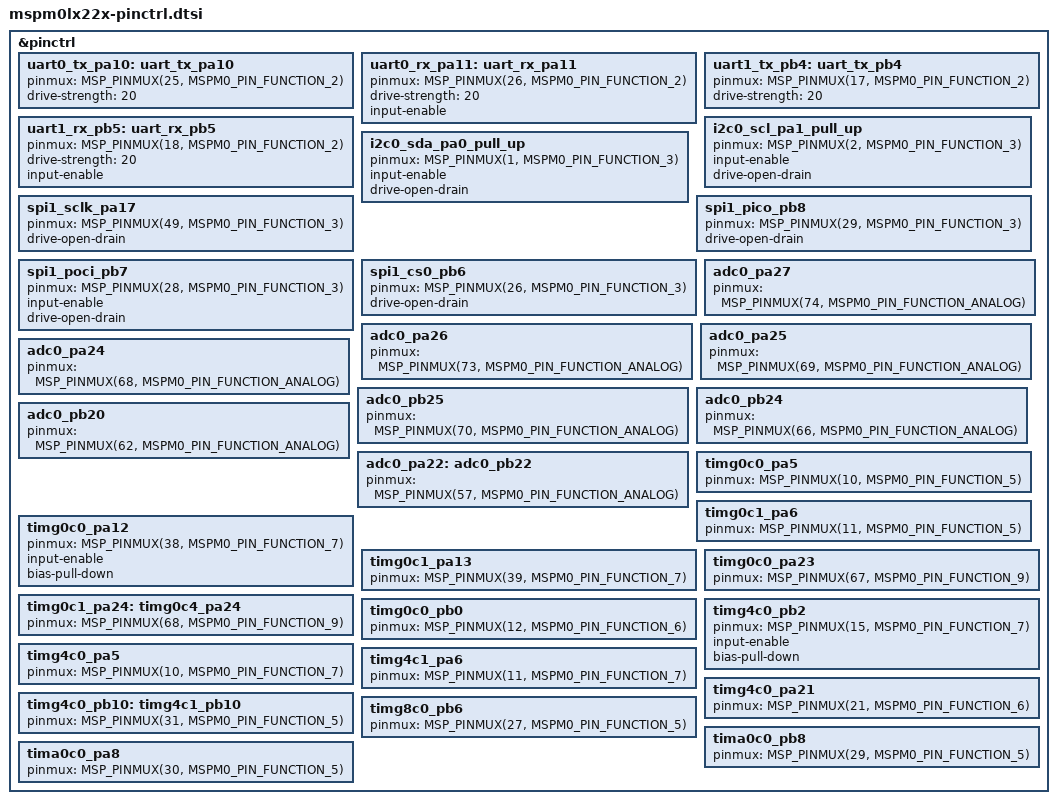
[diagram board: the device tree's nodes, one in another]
#include <dt-bindings/pinctrl/mspm0-pinctrl.h>

&pinctrl {
	/omit-if-no-ref/ uart0_tx_pa10: uart_tx_pa10 {
		pinmux = <MSP_PINMUX(25, MSPM0_PIN_FUNCTION_2)>;
		drive-strength = <20>;
	};

	/omit-if-no-ref/ uart0_rx_pa11: uart_rx_pa11 {
		pinmux = <MSP_PINMUX(26, MSPM0_PIN_FUNCTION_2)>;
		drive-strength = <20>;
		input-enable;
	};

	/omit-if-no-ref/ uart1_tx_pb4: uart_tx_pb4 {
		pinmux = <MSP_PINMUX(17, MSPM0_PIN_FUNCTION_2)>;
		drive-strength = <20>;
	};

	/omit-if-no-ref/ uart1_rx_pb5: uart_rx_pb5 {
		pinmux = <MSP_PINMUX(18, MSPM0_PIN_FUNCTION_2)>;
		drive-strength = <20>;
		input-enable;
	};

	/omit-if-no-ref/ i2c0_scl_pa1_pull_up: i2c0_scl_pa1_pull_up {
		pinmux = <MSP_PINMUX(2, MSPM0_PIN_FUNCTION_3)>;
		input-enable;
		drive-open-drain;
	};

	/omit-if-no-ref/ i2c0_sda_pa0_pull_up: i2c0_sda_pa0_pull_up {
		pinmux = <MSP_PINMUX(1, MSPM0_PIN_FUNCTION_3)>;
		input-enable;
		drive-open-drain;
	};

	/omit-if-no-ref/ spi1_sclk_pa17: spi1_sclk_pa17 {
		pinmux = <MSP_PINMUX(49, MSPM0_PIN_FUNCTION_3)>;
		drive-open-drain;
	};

	/omit-if-no-ref/ spi1_pico_pb8: spi1_pico_pb8 {
		pinmux = <MSP_PINMUX(29, MSPM0_PIN_FUNCTION_3)>;
		drive-open-drain;
	};

	/omit-if-no-ref/ spi1_poci_pb7: spi1_poci_pb7 {
		pinmux = <MSP_PINMUX(28, MSPM0_PIN_FUNCTION_3)>;
		input-enable;
		drive-open-drain;
	};

	/omit-if-no-ref/ spi1_cs0_pb6: spi1_cs0_pb6 {
		pinmux = <MSP_PINMUX(26, MSPM0_PIN_FUNCTION_3)>;
		drive-open-drain;
	};

	/omit-if-no-ref/ adc0_pa27: adc0_pa27 {
		pinmux = <MSP_PINMUX(74, MSPM0_PIN_FUNCTION_ANALOG)>;
	};

	/omit-if-no-ref/ adc0_pa26: adc0_pa26 {
		pinmux = <MSP_PINMUX(73, MSPM0_PIN_FUNCTION_ANALOG)>;
	};

	/omit-if-no-ref/ adc0_pa25: adc0_pa25 {
		pinmux = <MSP_PINMUX(69, MSPM0_PIN_FUNCTION_ANALOG)>;
	};

	/omit-if-no-ref/ adc0_pa24: adc0_pa24 {
		pinmux = <MSP_PINMUX(68, MSPM0_PIN_FUNCTION_ANALOG)>;
	};

	/omit-if-no-ref/ adc0_pb25: adc0_pb25 {
		pinmux = <MSP_PINMUX(70, MSPM0_PIN_FUNCTION_ANALOG)>;
	};

	/omit-if-no-ref/ adc0_pb24: adc0_pb24 {
		pinmux = <MSP_PINMUX(66, MSPM0_PIN_FUNCTION_ANALOG)>;
	};

	/omit-if-no-ref/ adc0_pb20: adc0_pb20 {
		pinmux = <MSP_PINMUX(62, MSPM0_PIN_FUNCTION_ANALOG)>;
	};

	/omit-if-no-ref/ adc0_pa22: adc0_pb22 {
		pinmux = <MSP_PINMUX(57, MSPM0_PIN_FUNCTION_ANALOG)>;
	};

	/omit-if-no-ref/ timg0c0_pa5: timg0c0_pa5 {
		pinmux = <MSP_PINMUX(10, MSPM0_PIN_FUNCTION_5)>;
	};

	/omit-if-no-ref/ timg0c1_pa6: timg0c1_pa6 {
		pinmux = <MSP_PINMUX(11, MSPM0_PIN_FUNCTION_5)>;
	};

	/omit-if-no-ref/ timg0c0_pa12: timg0c0_pa12 {
		pinmux = <MSP_PINMUX(38, MSPM0_PIN_FUNCTION_7)>;
		input-enable;
		bias-pull-down;
	};

	/omit-if-no-ref/ timg0c1_pa13: timg0c1_pa13 {
		pinmux = <MSP_PINMUX(39, MSPM0_PIN_FUNCTION_7)>;
	};

	/omit-if-no-ref/ timg0c0_pa23: timg0c0_pa23 {
		pinmux = <MSP_PINMUX(67, MSPM0_PIN_FUNCTION_9)>;
	};

	/omit-if-no-ref/ timg0c1_pa24: timg0c4_pa24 {
		pinmux = <MSP_PINMUX(68, MSPM0_PIN_FUNCTION_9)>;
	};

	/omit-if-no-ref/ timg0c0_pb0: timg0c0_pb0 {
		pinmux = <MSP_PINMUX(12, MSPM0_PIN_FUNCTION_6)>;
	};

	/omit-if-no-ref/ timg4c0_pb2: timg4c0_pb2 {
		pinmux = <MSP_PINMUX(15, MSPM0_PIN_FUNCTION_7)>;
		input-enable;
		bias-pull-down;
	};

	/omit-if-no-ref/ timg4c0_pa5: timg4c0_pa5 {
		pinmux = <MSP_PINMUX(10, MSPM0_PIN_FUNCTION_7)>;
	};

	/omit-if-no-ref/ timg4c1_pa6: timg4c1_pa6 {
		pinmux = <MSP_PINMUX(11, MSPM0_PIN_FUNCTION_7)>;
	};

	/omit-if-no-ref/ timg4c0_pa21: timg4c0_pa21 {
		pinmux = <MSP_PINMUX(21, MSPM0_PIN_FUNCTION_6)>;
	};

	/omit-if-no-ref/ timg4c0_pb10: timg4c1_pb10 {
		pinmux = <MSP_PINMUX(31, MSPM0_PIN_FUNCTION_5)>;
	};

	/omit-if-no-ref/ timg8c0_pb6: timg8c0_pb6 {
		pinmux = <MSP_PINMUX(27, MSPM0_PIN_FUNCTION_5)>;
	};

	/omit-if-no-ref/ tima0c0_pb8: tima0c0_pb8 {
		pinmux = <MSP_PINMUX(29, MSPM0_PIN_FUNCTION_5)>;
	};

	/omit-if-no-ref/ tima0c0_pa8: tima0c0_pa8{
		pinmux = <MSP_PINMUX(30, MSPM0_PIN_FUNCTION_5)>;
	};
};
